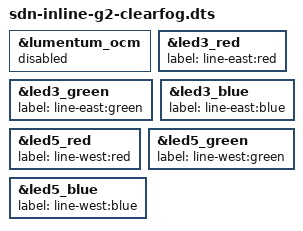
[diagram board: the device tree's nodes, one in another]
#include "sdn-roadm-clearfog.dtsi"
#include "clearfog-output-voa.dtsi"

&lumentum_ocm {
	status = "disabled";
};

&led3_red {
	label = "line-east:red";
};

&led3_green {
	label = "line-east:green";
};

&led3_blue {
	label = "line-east:blue";
};

&led5_red {
	label = "line-west:red";
};

&led5_green {
	label = "line-west:green";
};

&led5_blue {
	label = "line-west:blue";
};
